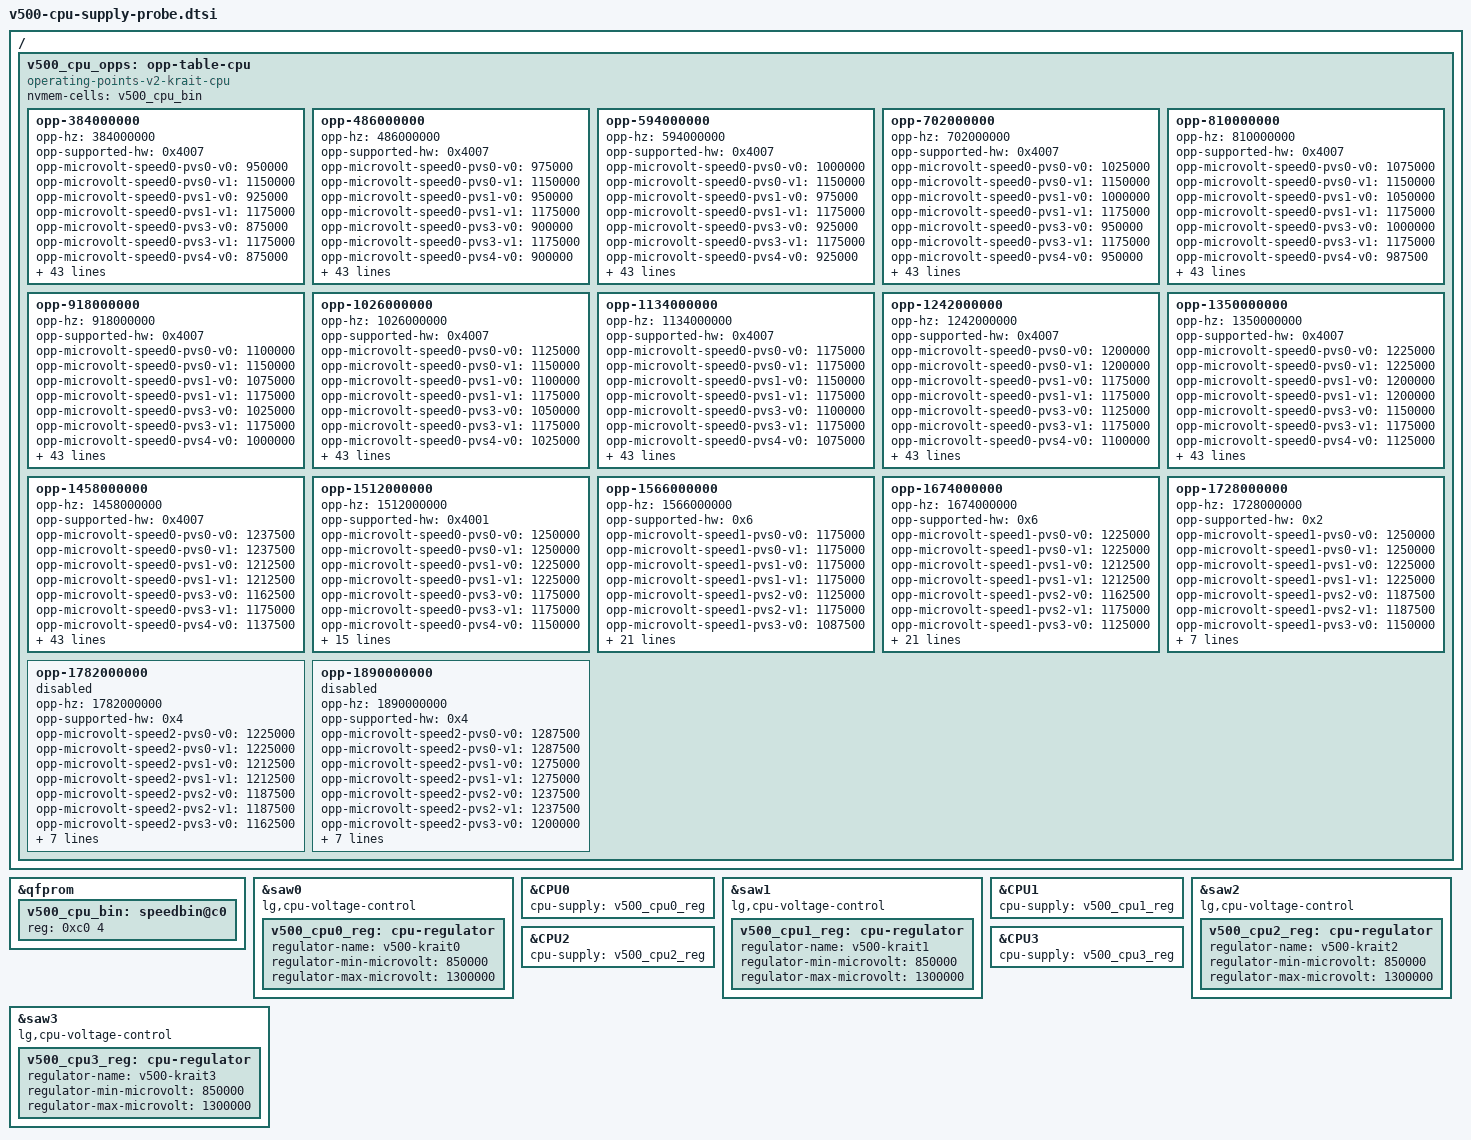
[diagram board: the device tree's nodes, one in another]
// SPDX-License-Identifier: GPL-2.0-only
/* LG acpuclock-8064.c, normal pvs_tables at 386aad263c38.
 * v0: base plus boost. v1: affected MIDRs need a 1150 mV floor before boost.
 * Only rows marked use_for_scaling by LG are CPUFreq operating points. */
&qfprom {
	v500_cpu_bin: speedbin@c0 {
		reg = <0xc0 4>;
	};
};

&saw0 {
	lg,cpu-voltage-control;
	v500_cpu0_reg: cpu-regulator {
		regulator-name = "v500-krait0";
		regulator-min-microvolt = <850000>;
		regulator-max-microvolt = <1300000>;
	};
};

&CPU0 {
	cpu-supply = <&v500_cpu0_reg>;
};

&saw1 {
	lg,cpu-voltage-control;
	v500_cpu1_reg: cpu-regulator {
		regulator-name = "v500-krait1";
		regulator-min-microvolt = <850000>;
		regulator-max-microvolt = <1300000>;
	};
};

&CPU1 {
	cpu-supply = <&v500_cpu1_reg>;
};

&saw2 {
	lg,cpu-voltage-control;
	v500_cpu2_reg: cpu-regulator {
		regulator-name = "v500-krait2";
		regulator-min-microvolt = <850000>;
		regulator-max-microvolt = <1300000>;
	};
};

&CPU2 {
	cpu-supply = <&v500_cpu2_reg>;
};

&saw3 {
	lg,cpu-voltage-control;
	v500_cpu3_reg: cpu-regulator {
		regulator-name = "v500-krait3";
		regulator-min-microvolt = <850000>;
		regulator-max-microvolt = <1300000>;
	};
};

&CPU3 {
	cpu-supply = <&v500_cpu3_reg>;
};

/ {
	/* Attach to CPUs only when L2 and shared RPM votes are implemented. */
	v500_cpu_opps: opp-table-cpu {
		compatible = "operating-points-v2-krait-cpu";
		nvmem-cells = <&v500_cpu_bin>;

		opp-384000000 {
			opp-hz = /bits/ 64 <384000000>;
			opp-supported-hw = <0x4007>;
			opp-microvolt-speed0-pvs0-v0 = <950000>;
			opp-microvolt-speed0-pvs0-v1 = <1150000>;
			opp-microvolt-speed0-pvs1-v0 = <925000>;
			opp-microvolt-speed0-pvs1-v1 = <1175000>;
			opp-microvolt-speed0-pvs3-v0 = <875000>;
			opp-microvolt-speed0-pvs3-v1 = <1175000>;
			opp-microvolt-speed0-pvs4-v0 = <875000>;
			opp-microvolt-speed0-pvs4-v1 = <1175000>;
			opp-microvolt-speed1-pvs0-v0 = <950000>;
			opp-microvolt-speed1-pvs0-v1 = <1150000>;
			opp-microvolt-speed1-pvs1-v0 = <975000>;
			opp-microvolt-speed1-pvs1-v1 = <1175000>;
			opp-microvolt-speed1-pvs2-v0 = <950000>;
			opp-microvolt-speed1-pvs2-v1 = <1175000>;
			opp-microvolt-speed1-pvs3-v0 = <925000>;
			opp-microvolt-speed1-pvs3-v1 = <1175000>;
			opp-microvolt-speed1-pvs4-v0 = <900000>;
			opp-microvolt-speed1-pvs4-v1 = <1175000>;
			opp-microvolt-speed1-pvs5-v0 = <900000>;
			opp-microvolt-speed1-pvs5-v1 = <1175000>;
			opp-microvolt-speed1-pvs6-v0 = <900000>;
			opp-microvolt-speed1-pvs6-v1 = <1175000>;
			opp-microvolt-speed2-pvs0-v0 = <950000>;
			opp-microvolt-speed2-pvs0-v1 = <1150000>;
			opp-microvolt-speed2-pvs1-v0 = <950000>;
			opp-microvolt-speed2-pvs1-v1 = <1175000>;
			opp-microvolt-speed2-pvs2-v0 = <925000>;
			opp-microvolt-speed2-pvs2-v1 = <1175000>;
			opp-microvolt-speed2-pvs3-v0 = <925000>;
			opp-microvolt-speed2-pvs3-v1 = <1175000>;
			opp-microvolt-speed2-pvs4-v0 = <900000>;
			opp-microvolt-speed2-pvs4-v1 = <1175000>;
			opp-microvolt-speed2-pvs5-v0 = <900000>;
			opp-microvolt-speed2-pvs5-v1 = <1175000>;
			opp-microvolt-speed2-pvs6-v0 = <900000>;
			opp-microvolt-speed2-pvs6-v1 = <1175000>;
			opp-microvolt-speed14-pvs0-v0 = <950000>;
			opp-microvolt-speed14-pvs0-v1 = <1150000>;
			opp-microvolt-speed14-pvs1-v0 = <975000>;
			opp-microvolt-speed14-pvs1-v1 = <1175000>;
			opp-microvolt-speed14-pvs2-v0 = <950000>;
			opp-microvolt-speed14-pvs2-v1 = <1175000>;
			opp-microvolt-speed14-pvs3-v0 = <925000>;
			opp-microvolt-speed14-pvs3-v1 = <1175000>;
			opp-microvolt-speed14-pvs4-v0 = <900000>;
			opp-microvolt-speed14-pvs4-v1 = <1175000>;
			opp-microvolt-speed14-pvs5-v0 = <900000>;
			opp-microvolt-speed14-pvs5-v1 = <1175000>;
			opp-microvolt-speed14-pvs6-v0 = <900000>;
			opp-microvolt-speed14-pvs6-v1 = <1175000>;
		};

		opp-486000000 {
			opp-hz = /bits/ 64 <486000000>;
			opp-supported-hw = <0x4007>;
			opp-microvolt-speed0-pvs0-v0 = <975000>;
			opp-microvolt-speed0-pvs0-v1 = <1150000>;
			opp-microvolt-speed0-pvs1-v0 = <950000>;
			opp-microvolt-speed0-pvs1-v1 = <1175000>;
			opp-microvolt-speed0-pvs3-v0 = <900000>;
			opp-microvolt-speed0-pvs3-v1 = <1175000>;
			opp-microvolt-speed0-pvs4-v0 = <900000>;
			opp-microvolt-speed0-pvs4-v1 = <1175000>;
			opp-microvolt-speed1-pvs0-v0 = <950000>;
			opp-microvolt-speed1-pvs0-v1 = <1150000>;
			opp-microvolt-speed1-pvs1-v0 = <975000>;
			opp-microvolt-speed1-pvs1-v1 = <1175000>;
			opp-microvolt-speed1-pvs2-v0 = <950000>;
			opp-microvolt-speed1-pvs2-v1 = <1175000>;
			opp-microvolt-speed1-pvs3-v0 = <925000>;
			opp-microvolt-speed1-pvs3-v1 = <1175000>;
			opp-microvolt-speed1-pvs4-v0 = <900000>;
			opp-microvolt-speed1-pvs4-v1 = <1175000>;
			opp-microvolt-speed1-pvs5-v0 = <900000>;
			opp-microvolt-speed1-pvs5-v1 = <1175000>;
			opp-microvolt-speed1-pvs6-v0 = <900000>;
			opp-microvolt-speed1-pvs6-v1 = <1175000>;
			opp-microvolt-speed2-pvs0-v0 = <950000>;
			opp-microvolt-speed2-pvs0-v1 = <1150000>;
			opp-microvolt-speed2-pvs1-v0 = <950000>;
			opp-microvolt-speed2-pvs1-v1 = <1175000>;
			opp-microvolt-speed2-pvs2-v0 = <925000>;
			opp-microvolt-speed2-pvs2-v1 = <1175000>;
			opp-microvolt-speed2-pvs3-v0 = <925000>;
			opp-microvolt-speed2-pvs3-v1 = <1175000>;
			opp-microvolt-speed2-pvs4-v0 = <900000>;
			opp-microvolt-speed2-pvs4-v1 = <1175000>;
			opp-microvolt-speed2-pvs5-v0 = <900000>;
			opp-microvolt-speed2-pvs5-v1 = <1175000>;
			opp-microvolt-speed2-pvs6-v0 = <900000>;
			opp-microvolt-speed2-pvs6-v1 = <1175000>;
			opp-microvolt-speed14-pvs0-v0 = <950000>;
			opp-microvolt-speed14-pvs0-v1 = <1150000>;
			opp-microvolt-speed14-pvs1-v0 = <975000>;
			opp-microvolt-speed14-pvs1-v1 = <1175000>;
			opp-microvolt-speed14-pvs2-v0 = <950000>;
			opp-microvolt-speed14-pvs2-v1 = <1175000>;
			opp-microvolt-speed14-pvs3-v0 = <925000>;
			opp-microvolt-speed14-pvs3-v1 = <1175000>;
			opp-microvolt-speed14-pvs4-v0 = <900000>;
			opp-microvolt-speed14-pvs4-v1 = <1175000>;
			opp-microvolt-speed14-pvs5-v0 = <900000>;
			opp-microvolt-speed14-pvs5-v1 = <1175000>;
			opp-microvolt-speed14-pvs6-v0 = <900000>;
			opp-microvolt-speed14-pvs6-v1 = <1175000>;
		};

		opp-594000000 {
			opp-hz = /bits/ 64 <594000000>;
			opp-supported-hw = <0x4007>;
			opp-microvolt-speed0-pvs0-v0 = <1000000>;
			opp-microvolt-speed0-pvs0-v1 = <1150000>;
			opp-microvolt-speed0-pvs1-v0 = <975000>;
			opp-microvolt-speed0-pvs1-v1 = <1175000>;
			opp-microvolt-speed0-pvs3-v0 = <925000>;
			opp-microvolt-speed0-pvs3-v1 = <1175000>;
			opp-microvolt-speed0-pvs4-v0 = <925000>;
			opp-microvolt-speed0-pvs4-v1 = <1175000>;
			opp-microvolt-speed1-pvs0-v0 = <950000>;
			opp-microvolt-speed1-pvs0-v1 = <1150000>;
			opp-microvolt-speed1-pvs1-v0 = <975000>;
			opp-microvolt-speed1-pvs1-v1 = <1175000>;
			opp-microvolt-speed1-pvs2-v0 = <950000>;
			opp-microvolt-speed1-pvs2-v1 = <1175000>;
			opp-microvolt-speed1-pvs3-v0 = <925000>;
			opp-microvolt-speed1-pvs3-v1 = <1175000>;
			opp-microvolt-speed1-pvs4-v0 = <900000>;
			opp-microvolt-speed1-pvs4-v1 = <1175000>;
			opp-microvolt-speed1-pvs5-v0 = <900000>;
			opp-microvolt-speed1-pvs5-v1 = <1175000>;
			opp-microvolt-speed1-pvs6-v0 = <900000>;
			opp-microvolt-speed1-pvs6-v1 = <1175000>;
			opp-microvolt-speed2-pvs0-v0 = <950000>;
			opp-microvolt-speed2-pvs0-v1 = <1150000>;
			opp-microvolt-speed2-pvs1-v0 = <950000>;
			opp-microvolt-speed2-pvs1-v1 = <1175000>;
			opp-microvolt-speed2-pvs2-v0 = <925000>;
			opp-microvolt-speed2-pvs2-v1 = <1175000>;
			opp-microvolt-speed2-pvs3-v0 = <925000>;
			opp-microvolt-speed2-pvs3-v1 = <1175000>;
			opp-microvolt-speed2-pvs4-v0 = <900000>;
			opp-microvolt-speed2-pvs4-v1 = <1175000>;
			opp-microvolt-speed2-pvs5-v0 = <900000>;
			opp-microvolt-speed2-pvs5-v1 = <1175000>;
			opp-microvolt-speed2-pvs6-v0 = <900000>;
			opp-microvolt-speed2-pvs6-v1 = <1175000>;
			opp-microvolt-speed14-pvs0-v0 = <950000>;
			opp-microvolt-speed14-pvs0-v1 = <1150000>;
			opp-microvolt-speed14-pvs1-v0 = <975000>;
			opp-microvolt-speed14-pvs1-v1 = <1175000>;
			opp-microvolt-speed14-pvs2-v0 = <950000>;
			opp-microvolt-speed14-pvs2-v1 = <1175000>;
			opp-microvolt-speed14-pvs3-v0 = <925000>;
			opp-microvolt-speed14-pvs3-v1 = <1175000>;
			opp-microvolt-speed14-pvs4-v0 = <900000>;
			opp-microvolt-speed14-pvs4-v1 = <1175000>;
			opp-microvolt-speed14-pvs5-v0 = <900000>;
			opp-microvolt-speed14-pvs5-v1 = <1175000>;
			opp-microvolt-speed14-pvs6-v0 = <900000>;
			opp-microvolt-speed14-pvs6-v1 = <1175000>;
		};

		opp-702000000 {
			opp-hz = /bits/ 64 <702000000>;
			opp-supported-hw = <0x4007>;
			opp-microvolt-speed0-pvs0-v0 = <1025000>;
			opp-microvolt-speed0-pvs0-v1 = <1150000>;
			opp-microvolt-speed0-pvs1-v0 = <1000000>;
			opp-microvolt-speed0-pvs1-v1 = <1175000>;
			opp-microvolt-speed0-pvs3-v0 = <950000>;
			opp-microvolt-speed0-pvs3-v1 = <1175000>;
			opp-microvolt-speed0-pvs4-v0 = <950000>;
			opp-microvolt-speed0-pvs4-v1 = <1175000>;
			opp-microvolt-speed1-pvs0-v0 = <962500>;
			opp-microvolt-speed1-pvs0-v1 = <1150000>;
			opp-microvolt-speed1-pvs1-v0 = <987500>;
			opp-microvolt-speed1-pvs1-v1 = <1175000>;
			opp-microvolt-speed1-pvs2-v0 = <950000>;
			opp-microvolt-speed1-pvs2-v1 = <1175000>;
			opp-microvolt-speed1-pvs3-v0 = <925000>;
			opp-microvolt-speed1-pvs3-v1 = <1175000>;
			opp-microvolt-speed1-pvs4-v0 = <900000>;
			opp-microvolt-speed1-pvs4-v1 = <1175000>;
			opp-microvolt-speed1-pvs5-v0 = <900000>;
			opp-microvolt-speed1-pvs5-v1 = <1175000>;
			opp-microvolt-speed1-pvs6-v0 = <900000>;
			opp-microvolt-speed1-pvs6-v1 = <1175000>;
			opp-microvolt-speed2-pvs0-v0 = <950000>;
			opp-microvolt-speed2-pvs0-v1 = <1150000>;
			opp-microvolt-speed2-pvs1-v0 = <950000>;
			opp-microvolt-speed2-pvs1-v1 = <1175000>;
			opp-microvolt-speed2-pvs2-v0 = <925000>;
			opp-microvolt-speed2-pvs2-v1 = <1175000>;
			opp-microvolt-speed2-pvs3-v0 = <925000>;
			opp-microvolt-speed2-pvs3-v1 = <1175000>;
			opp-microvolt-speed2-pvs4-v0 = <900000>;
			opp-microvolt-speed2-pvs4-v1 = <1175000>;
			opp-microvolt-speed2-pvs5-v0 = <900000>;
			opp-microvolt-speed2-pvs5-v1 = <1175000>;
			opp-microvolt-speed2-pvs6-v0 = <900000>;
			opp-microvolt-speed2-pvs6-v1 = <1175000>;
			opp-microvolt-speed14-pvs0-v0 = <962500>;
			opp-microvolt-speed14-pvs0-v1 = <1150000>;
			opp-microvolt-speed14-pvs1-v0 = <987500>;
			opp-microvolt-speed14-pvs1-v1 = <1175000>;
			opp-microvolt-speed14-pvs2-v0 = <950000>;
			opp-microvolt-speed14-pvs2-v1 = <1175000>;
			opp-microvolt-speed14-pvs3-v0 = <925000>;
			opp-microvolt-speed14-pvs3-v1 = <1175000>;
			opp-microvolt-speed14-pvs4-v0 = <900000>;
			opp-microvolt-speed14-pvs4-v1 = <1175000>;
			opp-microvolt-speed14-pvs5-v0 = <900000>;
			opp-microvolt-speed14-pvs5-v1 = <1175000>;
			opp-microvolt-speed14-pvs6-v0 = <900000>;
			opp-microvolt-speed14-pvs6-v1 = <1175000>;
		};

		opp-810000000 {
			opp-hz = /bits/ 64 <810000000>;
			opp-supported-hw = <0x4007>;
			opp-microvolt-speed0-pvs0-v0 = <1075000>;
			opp-microvolt-speed0-pvs0-v1 = <1150000>;
			opp-microvolt-speed0-pvs1-v0 = <1050000>;
			opp-microvolt-speed0-pvs1-v1 = <1175000>;
			opp-microvolt-speed0-pvs3-v0 = <1000000>;
			opp-microvolt-speed0-pvs3-v1 = <1175000>;
			opp-microvolt-speed0-pvs4-v0 = <987500>;
			opp-microvolt-speed0-pvs4-v1 = <1175000>;
			opp-microvolt-speed1-pvs0-v0 = <1000000>;
			opp-microvolt-speed1-pvs0-v1 = <1150000>;
			opp-microvolt-speed1-pvs1-v0 = <1000000>;
			opp-microvolt-speed1-pvs1-v1 = <1175000>;
			opp-microvolt-speed1-pvs2-v0 = <962500>;
			opp-microvolt-speed1-pvs2-v1 = <1175000>;
			opp-microvolt-speed1-pvs3-v0 = <925000>;
			opp-microvolt-speed1-pvs3-v1 = <1175000>;
			opp-microvolt-speed1-pvs4-v0 = <912500>;
			opp-microvolt-speed1-pvs4-v1 = <1175000>;
			opp-microvolt-speed1-pvs5-v0 = <912500>;
			opp-microvolt-speed1-pvs5-v1 = <1175000>;
			opp-microvolt-speed1-pvs6-v0 = <912500>;
			opp-microvolt-speed1-pvs6-v1 = <1175000>;
			opp-microvolt-speed2-pvs0-v0 = <962500>;
			opp-microvolt-speed2-pvs0-v1 = <1150000>;
			opp-microvolt-speed2-pvs1-v0 = <962500>;
			opp-microvolt-speed2-pvs1-v1 = <1175000>;
			opp-microvolt-speed2-pvs2-v0 = <937500>;
			opp-microvolt-speed2-pvs2-v1 = <1175000>;
			opp-microvolt-speed2-pvs3-v0 = <925000>;
			opp-microvolt-speed2-pvs3-v1 = <1175000>;
			opp-microvolt-speed2-pvs4-v0 = <912500>;
			opp-microvolt-speed2-pvs4-v1 = <1175000>;
			opp-microvolt-speed2-pvs5-v0 = <912500>;
			opp-microvolt-speed2-pvs5-v1 = <1175000>;
			opp-microvolt-speed2-pvs6-v0 = <912500>;
			opp-microvolt-speed2-pvs6-v1 = <1175000>;
			opp-microvolt-speed14-pvs0-v0 = <1000000>;
			opp-microvolt-speed14-pvs0-v1 = <1150000>;
			opp-microvolt-speed14-pvs1-v0 = <1000000>;
			opp-microvolt-speed14-pvs1-v1 = <1175000>;
			opp-microvolt-speed14-pvs2-v0 = <962500>;
			opp-microvolt-speed14-pvs2-v1 = <1175000>;
			opp-microvolt-speed14-pvs3-v0 = <925000>;
			opp-microvolt-speed14-pvs3-v1 = <1175000>;
			opp-microvolt-speed14-pvs4-v0 = <912500>;
			opp-microvolt-speed14-pvs4-v1 = <1175000>;
			opp-microvolt-speed14-pvs5-v0 = <912500>;
			opp-microvolt-speed14-pvs5-v1 = <1175000>;
			opp-microvolt-speed14-pvs6-v0 = <912500>;
			opp-microvolt-speed14-pvs6-v1 = <1175000>;
		};

		opp-918000000 {
			opp-hz = /bits/ 64 <918000000>;
			opp-supported-hw = <0x4007>;
			opp-microvolt-speed0-pvs0-v0 = <1100000>;
			opp-microvolt-speed0-pvs0-v1 = <1150000>;
			opp-microvolt-speed0-pvs1-v0 = <1075000>;
			opp-microvolt-speed0-pvs1-v1 = <1175000>;
			opp-microvolt-speed0-pvs3-v0 = <1025000>;
			opp-microvolt-speed0-pvs3-v1 = <1175000>;
			opp-microvolt-speed0-pvs4-v0 = <1000000>;
			opp-microvolt-speed0-pvs4-v1 = <1175000>;
			opp-microvolt-speed1-pvs0-v0 = <1025000>;
			opp-microvolt-speed1-pvs0-v1 = <1150000>;
			opp-microvolt-speed1-pvs1-v0 = <1025000>;
			opp-microvolt-speed1-pvs1-v1 = <1175000>;
			opp-microvolt-speed1-pvs2-v0 = <975000>;
			opp-microvolt-speed1-pvs2-v1 = <1175000>;
			opp-microvolt-speed1-pvs3-v0 = <950000>;
			opp-microvolt-speed1-pvs3-v1 = <1175000>;
			opp-microvolt-speed1-pvs4-v0 = <925000>;
			opp-microvolt-speed1-pvs4-v1 = <1175000>;
			opp-microvolt-speed1-pvs5-v0 = <925000>;
			opp-microvolt-speed1-pvs5-v1 = <1175000>;
			opp-microvolt-speed1-pvs6-v0 = <925000>;
			opp-microvolt-speed1-pvs6-v1 = <1175000>;
			opp-microvolt-speed2-pvs0-v0 = <975000>;
			opp-microvolt-speed2-pvs0-v1 = <1150000>;
			opp-microvolt-speed2-pvs1-v0 = <975000>;
			opp-microvolt-speed2-pvs1-v1 = <1175000>;
			opp-microvolt-speed2-pvs2-v0 = <950000>;
			opp-microvolt-speed2-pvs2-v1 = <1175000>;
			opp-microvolt-speed2-pvs3-v0 = <937500>;
			opp-microvolt-speed2-pvs3-v1 = <1175000>;
			opp-microvolt-speed2-pvs4-v0 = <925000>;
			opp-microvolt-speed2-pvs4-v1 = <1175000>;
			opp-microvolt-speed2-pvs5-v0 = <925000>;
			opp-microvolt-speed2-pvs5-v1 = <1175000>;
			opp-microvolt-speed2-pvs6-v0 = <925000>;
			opp-microvolt-speed2-pvs6-v1 = <1175000>;
			opp-microvolt-speed14-pvs0-v0 = <1025000>;
			opp-microvolt-speed14-pvs0-v1 = <1150000>;
			opp-microvolt-speed14-pvs1-v0 = <1025000>;
			opp-microvolt-speed14-pvs1-v1 = <1175000>;
			opp-microvolt-speed14-pvs2-v0 = <975000>;
			opp-microvolt-speed14-pvs2-v1 = <1175000>;
			opp-microvolt-speed14-pvs3-v0 = <950000>;
			opp-microvolt-speed14-pvs3-v1 = <1175000>;
			opp-microvolt-speed14-pvs4-v0 = <925000>;
			opp-microvolt-speed14-pvs4-v1 = <1175000>;
			opp-microvolt-speed14-pvs5-v0 = <925000>;
			opp-microvolt-speed14-pvs5-v1 = <1175000>;
			opp-microvolt-speed14-pvs6-v0 = <925000>;
			opp-microvolt-speed14-pvs6-v1 = <1175000>;
		};

		opp-1026000000 {
			opp-hz = /bits/ 64 <1026000000>;
			opp-supported-hw = <0x4007>;
			opp-microvolt-speed0-pvs0-v0 = <1125000>;
			opp-microvolt-speed0-pvs0-v1 = <1150000>;
			opp-microvolt-speed0-pvs1-v0 = <1100000>;
			opp-microvolt-speed0-pvs1-v1 = <1175000>;
			opp-microvolt-speed0-pvs3-v0 = <1050000>;
			opp-microvolt-speed0-pvs3-v1 = <1175000>;
			opp-microvolt-speed0-pvs4-v0 = <1025000>;
			opp-microvolt-speed0-pvs4-v1 = <1175000>;
			opp-microvolt-speed1-pvs0-v0 = <1037500>;
			opp-microvolt-speed1-pvs0-v1 = <1150000>;
			opp-microvolt-speed1-pvs1-v0 = <1037500>;
			opp-microvolt-speed1-pvs1-v1 = <1175000>;
			opp-microvolt-speed1-pvs2-v0 = <1000000>;
			opp-microvolt-speed1-pvs2-v1 = <1175000>;
			opp-microvolt-speed1-pvs3-v0 = <975000>;
			opp-microvolt-speed1-pvs3-v1 = <1175000>;
			opp-microvolt-speed1-pvs4-v0 = <950000>;
			opp-microvolt-speed1-pvs4-v1 = <1175000>;
			opp-microvolt-speed1-pvs5-v0 = <950000>;
			opp-microvolt-speed1-pvs5-v1 = <1175000>;
			opp-microvolt-speed1-pvs6-v0 = <950000>;
			opp-microvolt-speed1-pvs6-v1 = <1175000>;
			opp-microvolt-speed2-pvs0-v0 = <1000000>;
			opp-microvolt-speed2-pvs0-v1 = <1150000>;
			opp-microvolt-speed2-pvs1-v0 = <1000000>;
			opp-microvolt-speed2-pvs1-v1 = <1175000>;
			opp-microvolt-speed2-pvs2-v0 = <975000>;
			opp-microvolt-speed2-pvs2-v1 = <1175000>;
			opp-microvolt-speed2-pvs3-v0 = <962500>;
			opp-microvolt-speed2-pvs3-v1 = <1175000>;
			opp-microvolt-speed2-pvs4-v0 = <950000>;
			opp-microvolt-speed2-pvs4-v1 = <1175000>;
			opp-microvolt-speed2-pvs5-v0 = <950000>;
			opp-microvolt-speed2-pvs5-v1 = <1175000>;
			opp-microvolt-speed2-pvs6-v0 = <950000>;
			opp-microvolt-speed2-pvs6-v1 = <1175000>;
			opp-microvolt-speed14-pvs0-v0 = <1037500>;
			opp-microvolt-speed14-pvs0-v1 = <1150000>;
			opp-microvolt-speed14-pvs1-v0 = <1037500>;
			opp-microvolt-speed14-pvs1-v1 = <1175000>;
			opp-microvolt-speed14-pvs2-v0 = <1000000>;
			opp-microvolt-speed14-pvs2-v1 = <1175000>;
			opp-microvolt-speed14-pvs3-v0 = <975000>;
			opp-microvolt-speed14-pvs3-v1 = <1175000>;
			opp-microvolt-speed14-pvs4-v0 = <950000>;
			opp-microvolt-speed14-pvs4-v1 = <1175000>;
			opp-microvolt-speed14-pvs5-v0 = <950000>;
			opp-microvolt-speed14-pvs5-v1 = <1175000>;
			opp-microvolt-speed14-pvs6-v0 = <950000>;
			opp-microvolt-speed14-pvs6-v1 = <1175000>;
		};

		opp-1134000000 {
			opp-hz = /bits/ 64 <1134000000>;
			opp-supported-hw = <0x4007>;
			opp-microvolt-speed0-pvs0-v0 = <1175000>;
			opp-microvolt-speed0-pvs0-v1 = <1175000>;
			opp-microvolt-speed0-pvs1-v0 = <1150000>;
			opp-microvolt-speed0-pvs1-v1 = <1175000>;
			opp-microvolt-speed0-pvs3-v0 = <1100000>;
			opp-microvolt-speed0-pvs3-v1 = <1175000>;
			opp-microvolt-speed0-pvs4-v0 = <1075000>;
			opp-microvolt-speed0-pvs4-v1 = <1175000>;
			opp-microvolt-speed1-pvs0-v0 = <1075000>;
			opp-microvolt-speed1-pvs0-v1 = <1150000>;
			opp-microvolt-speed1-pvs1-v0 = <1062500>;
			opp-microvolt-speed1-pvs1-v1 = <1175000>;
			opp-microvolt-speed1-pvs2-v0 = <1025000>;
			opp-microvolt-speed1-pvs2-v1 = <1175000>;
			opp-microvolt-speed1-pvs3-v0 = <1000000>;
			opp-microvolt-speed1-pvs3-v1 = <1175000>;
			opp-microvolt-speed1-pvs4-v0 = <975000>;
			opp-microvolt-speed1-pvs4-v1 = <1175000>;
			opp-microvolt-speed1-pvs5-v0 = <962500>;
			opp-microvolt-speed1-pvs5-v1 = <1175000>;
			opp-microvolt-speed1-pvs6-v0 = <962500>;
			opp-microvolt-speed1-pvs6-v1 = <1175000>;
			opp-microvolt-speed2-pvs0-v0 = <1025000>;
			opp-microvolt-speed2-pvs0-v1 = <1150000>;
			opp-microvolt-speed2-pvs1-v0 = <1025000>;
			opp-microvolt-speed2-pvs1-v1 = <1175000>;
			opp-microvolt-speed2-pvs2-v0 = <1000000>;
			opp-microvolt-speed2-pvs2-v1 = <1175000>;
			opp-microvolt-speed2-pvs3-v0 = <987500>;
			opp-microvolt-speed2-pvs3-v1 = <1175000>;
			opp-microvolt-speed2-pvs4-v0 = <975000>;
			opp-microvolt-speed2-pvs4-v1 = <1175000>;
			opp-microvolt-speed2-pvs5-v0 = <962500>;
			opp-microvolt-speed2-pvs5-v1 = <1175000>;
			opp-microvolt-speed2-pvs6-v0 = <962500>;
			opp-microvolt-speed2-pvs6-v1 = <1175000>;
			opp-microvolt-speed14-pvs0-v0 = <1075000>;
			opp-microvolt-speed14-pvs0-v1 = <1150000>;
			opp-microvolt-speed14-pvs1-v0 = <1062500>;
			opp-microvolt-speed14-pvs1-v1 = <1175000>;
			opp-microvolt-speed14-pvs2-v0 = <1025000>;
			opp-microvolt-speed14-pvs2-v1 = <1175000>;
			opp-microvolt-speed14-pvs3-v0 = <1000000>;
			opp-microvolt-speed14-pvs3-v1 = <1175000>;
			opp-microvolt-speed14-pvs4-v0 = <975000>;
			opp-microvolt-speed14-pvs4-v1 = <1175000>;
			opp-microvolt-speed14-pvs5-v0 = <962500>;
			opp-microvolt-speed14-pvs5-v1 = <1175000>;
			opp-microvolt-speed14-pvs6-v0 = <962500>;
			opp-microvolt-speed14-pvs6-v1 = <1175000>;
		};

		opp-1242000000 {
			opp-hz = /bits/ 64 <1242000000>;
			opp-supported-hw = <0x4007>;
			opp-microvolt-speed0-pvs0-v0 = <1200000>;
			opp-microvolt-speed0-pvs0-v1 = <1200000>;
			opp-microvolt-speed0-pvs1-v0 = <1175000>;
			opp-microvolt-speed0-pvs1-v1 = <1175000>;
			opp-microvolt-speed0-pvs3-v0 = <1125000>;
			opp-microvolt-speed0-pvs3-v1 = <1175000>;
			opp-microvolt-speed0-pvs4-v0 = <1100000>;
			opp-microvolt-speed0-pvs4-v1 = <1175000>;
			opp-microvolt-speed1-pvs0-v0 = <1087500>;
			opp-microvolt-speed1-pvs0-v1 = <1150000>;
			opp-microvolt-speed1-pvs1-v0 = <1075000>;
			opp-microvolt-speed1-pvs1-v1 = <1175000>;
			opp-microvolt-speed1-pvs2-v0 = <1037500>;
			opp-microvolt-speed1-pvs2-v1 = <1175000>;
			opp-microvolt-speed1-pvs3-v0 = <1012500>;
			opp-microvolt-speed1-pvs3-v1 = <1175000>;
			opp-microvolt-speed1-pvs4-v0 = <987500>;
			opp-microvolt-speed1-pvs4-v1 = <1175000>;
			opp-microvolt-speed1-pvs5-v0 = <975000>;
			opp-microvolt-speed1-pvs5-v1 = <1175000>;
			opp-microvolt-speed1-pvs6-v0 = <975000>;
			opp-microvolt-speed1-pvs6-v1 = <1175000>;
			opp-microvolt-speed2-pvs0-v0 = <1037500>;
			opp-microvolt-speed2-pvs0-v1 = <1150000>;
			opp-microvolt-speed2-pvs1-v0 = <1037500>;
			opp-microvolt-speed2-pvs1-v1 = <1175000>;
			opp-microvolt-speed2-pvs2-v0 = <1012500>;
			opp-microvolt-speed2-pvs2-v1 = <1175000>;
			opp-microvolt-speed2-pvs3-v0 = <1000000>;
			opp-microvolt-speed2-pvs3-v1 = <1175000>;
			opp-microvolt-speed2-pvs4-v0 = <987500>;
			opp-microvolt-speed2-pvs4-v1 = <1175000>;
			opp-microvolt-speed2-pvs5-v0 = <975000>;
			opp-microvolt-speed2-pvs5-v1 = <1175000>;
			opp-microvolt-speed2-pvs6-v0 = <975000>;
			opp-microvolt-speed2-pvs6-v1 = <1175000>;
			opp-microvolt-speed14-pvs0-v0 = <1087500>;
			opp-microvolt-speed14-pvs0-v1 = <1150000>;
			opp-microvolt-speed14-pvs1-v0 = <1075000>;
			opp-microvolt-speed14-pvs1-v1 = <1175000>;
			opp-microvolt-speed14-pvs2-v0 = <1037500>;
			opp-microvolt-speed14-pvs2-v1 = <1175000>;
			opp-microvolt-speed14-pvs3-v0 = <1012500>;
			opp-microvolt-speed14-pvs3-v1 = <1175000>;
			opp-microvolt-speed14-pvs4-v0 = <987500>;
			opp-microvolt-speed14-pvs4-v1 = <1175000>;
			opp-microvolt-speed14-pvs5-v0 = <975000>;
			opp-microvolt-speed14-pvs5-v1 = <1175000>;
			opp-microvolt-speed14-pvs6-v0 = <975000>;
			opp-microvolt-speed14-pvs6-v1 = <1175000>;
		};

		opp-1350000000 {
			opp-hz = /bits/ 64 <1350000000>;
			opp-supported-hw = <0x4007>;
			opp-microvolt-speed0-pvs0-v0 = <1225000>;
			opp-microvolt-speed0-pvs0-v1 = <1225000>;
			opp-microvolt-speed0-pvs1-v0 = <1200000>;
			opp-microvolt-speed0-pvs1-v1 = <1200000>;
			opp-microvolt-speed0-pvs3-v0 = <1150000>;
			opp-microvolt-speed0-pvs3-v1 = <1175000>;
			opp-microvolt-speed0-pvs4-v0 = <1125000>;
			opp-microvolt-speed0-pvs4-v1 = <1175000>;
			opp-microvolt-speed1-pvs0-v0 = <1125000>;
			opp-microvolt-speed1-pvs0-v1 = <1150000>;
			opp-microvolt-speed1-pvs1-v0 = <1112500>;
			opp-microvolt-speed1-pvs1-v1 = <1175000>;
			opp-microvolt-speed1-pvs2-v0 = <1062500>;
			opp-microvolt-speed1-pvs2-v1 = <1175000>;
			opp-microvolt-speed1-pvs3-v0 = <1025000>;
			opp-microvolt-speed1-pvs3-v1 = <1175000>;
			opp-microvolt-speed1-pvs4-v0 = <1000000>;
			opp-microvolt-speed1-pvs4-v1 = <1175000>;
			opp-microvolt-speed1-pvs5-v0 = <987500>;
			opp-microvolt-speed1-pvs5-v1 = <1175000>;
			opp-microvolt-speed1-pvs6-v0 = <987500>;
			opp-microvolt-speed1-pvs6-v1 = <1175000>;
			opp-microvolt-speed2-pvs0-v0 = <1062500>;
			opp-microvolt-speed2-pvs0-v1 = <1150000>;
			opp-microvolt-speed2-pvs1-v0 = <1062500>;
			opp-microvolt-speed2-pvs1-v1 = <1175000>;
			opp-microvolt-speed2-pvs2-v0 = <1037500>;
			opp-microvolt-speed2-pvs2-v1 = <1175000>;
			opp-microvolt-speed2-pvs3-v0 = <1025000>;
			opp-microvolt-speed2-pvs3-v1 = <1175000>;
			opp-microvolt-speed2-pvs4-v0 = <1000000>;
			opp-microvolt-speed2-pvs4-v1 = <1175000>;
			opp-microvolt-speed2-pvs5-v0 = <987500>;
			opp-microvolt-speed2-pvs5-v1 = <1175000>;
			opp-microvolt-speed2-pvs6-v0 = <987500>;
			opp-microvolt-speed2-pvs6-v1 = <1175000>;
			opp-microvolt-speed14-pvs0-v0 = <1125000>;
			opp-microvolt-speed14-pvs0-v1 = <1150000>;
			opp-microvolt-speed14-pvs1-v0 = <1112500>;
			opp-microvolt-speed14-pvs1-v1 = <1175000>;
			opp-microvolt-speed14-pvs2-v0 = <1062500>;
			opp-microvolt-speed14-pvs2-v1 = <1175000>;
			opp-microvolt-speed14-pvs3-v0 = <1025000>;
			opp-microvolt-speed14-pvs3-v1 = <1175000>;
			opp-microvolt-speed14-pvs4-v0 = <1000000>;
			opp-microvolt-speed14-pvs4-v1 = <1175000>;
			opp-microvolt-speed14-pvs5-v0 = <987500>;
			opp-microvolt-speed14-pvs5-v1 = <1175000>;
			opp-microvolt-speed14-pvs6-v0 = <987500>;
			opp-microvolt-speed14-pvs6-v1 = <1175000>;
		};

		opp-1458000000 {
			opp-hz = /bits/ 64 <1458000000>;
			opp-supported-hw = <0x4007>;
			opp-microvolt-speed0-pvs0-v0 = <1237500>;
			opp-microvolt-speed0-pvs0-v1 = <1237500>;
			opp-microvolt-speed0-pvs1-v0 = <1212500>;
			opp-microvolt-speed0-pvs1-v1 = <1212500>;
			opp-microvolt-speed0-pvs3-v0 = <1162500>;
			opp-microvolt-speed0-pvs3-v1 = <1175000>;
			opp-microvolt-speed0-pvs4-v0 = <1137500>;
			opp-microvolt-speed0-pvs4-v1 = <1175000>;
			opp-microvolt-speed1-pvs0-v0 = <1150000>;
			opp-microvolt-speed1-pvs0-v1 = <1150000>;
			opp-microvolt-speed1-pvs1-v0 = <1137500>;
			opp-microvolt-speed1-pvs1-v1 = <1175000>;
			opp-microvolt-speed1-pvs2-v0 = <1100000>;
			opp-microvolt-speed1-pvs2-v1 = <1175000>;
			opp-microvolt-speed1-pvs3-v0 = <1062500>;
			opp-microvolt-speed1-pvs3-v1 = <1175000>;
			opp-microvolt-speed1-pvs4-v0 = <1025000>;
			opp-microvolt-speed1-pvs4-v1 = <1175000>;
			opp-microvolt-speed1-pvs5-v0 = <1012500>;
			opp-microvolt-speed1-pvs5-v1 = <1175000>;
			opp-microvolt-speed1-pvs6-v0 = <1000000>;
			opp-microvolt-speed1-pvs6-v1 = <1175000>;
			opp-microvolt-speed2-pvs0-v0 = <1100000>;
			opp-microvolt-speed2-pvs0-v1 = <1150000>;
			opp-microvolt-speed2-pvs1-v0 = <1100000>;
			opp-microvolt-speed2-pvs1-v1 = <1175000>;
			opp-microvolt-speed2-pvs2-v0 = <1075000>;
			opp-microvolt-speed2-pvs2-v1 = <1175000>;
			opp-microvolt-speed2-pvs3-v0 = <1050000>;
			opp-microvolt-speed2-pvs3-v1 = <1175000>;
			opp-microvolt-speed2-pvs4-v0 = <1025000>;
			opp-microvolt-speed2-pvs4-v1 = <1175000>;
			opp-microvolt-speed2-pvs5-v0 = <1012500>;
			opp-microvolt-speed2-pvs5-v1 = <1175000>;
			opp-microvolt-speed2-pvs6-v0 = <1000000>;
			opp-microvolt-speed2-pvs6-v1 = <1175000>;
			opp-microvolt-speed14-pvs0-v0 = <1150000>;
			opp-microvolt-speed14-pvs0-v1 = <1150000>;
			opp-microvolt-speed14-pvs1-v0 = <1137500>;
			opp-microvolt-speed14-pvs1-v1 = <1175000>;
			opp-microvolt-speed14-pvs2-v0 = <1100000>;
			opp-microvolt-speed14-pvs2-v1 = <1175000>;
			opp-microvolt-speed14-pvs3-v0 = <1062500>;
			opp-microvolt-speed14-pvs3-v1 = <1175000>;
			opp-microvolt-speed14-pvs4-v0 = <1025000>;
			opp-microvolt-speed14-pvs4-v1 = <1175000>;
			opp-microvolt-speed14-pvs5-v0 = <1012500>;
			opp-microvolt-speed14-pvs5-v1 = <1175000>;
			opp-microvolt-speed14-pvs6-v0 = <1000000>;
			opp-microvolt-speed14-pvs6-v1 = <1175000>;
		};

		opp-1512000000 {
			opp-hz = /bits/ 64 <1512000000>;
			opp-supported-hw = <0x4001>;
			opp-microvolt-speed0-pvs0-v0 = <1250000>;
			opp-microvolt-speed0-pvs0-v1 = <1250000>;
			opp-microvolt-speed0-pvs1-v0 = <1225000>;
			opp-microvolt-speed0-pvs1-v1 = <1225000>;
			opp-microvolt-speed0-pvs3-v0 = <1175000>;
			opp-microvolt-speed0-pvs3-v1 = <1175000>;
			opp-microvolt-speed0-pvs4-v0 = <1150000>;
			opp-microvolt-speed0-pvs4-v1 = <1175000>;
			opp-microvolt-speed14-pvs0-v0 = <1162500>;
			opp-microvolt-speed14-pvs0-v1 = <1162500>;
			opp-microvolt-speed14-pvs1-v0 = <1150000>;
			opp-microvolt-speed14-pvs1-v1 = <1175000>;
			opp-microvolt-speed14-pvs2-v0 = <1112500>;
			opp-microvolt-speed14-pvs2-v1 = <1175000>;
			opp-microvolt-speed14-pvs3-v0 = <1075000>;
			opp-microvolt-speed14-pvs3-v1 = <1175000>;
			opp-microvolt-speed14-pvs4-v0 = <1037500>;
			opp-microvolt-speed14-pvs4-v1 = <1175000>;
			opp-microvolt-speed14-pvs5-v0 = <1025000>;
			opp-microvolt-speed14-pvs5-v1 = <1175000>;
			opp-microvolt-speed14-pvs6-v0 = <1012500>;
			opp-microvolt-speed14-pvs6-v1 = <1175000>;
		};

		opp-1566000000 {
			opp-hz = /bits/ 64 <1566000000>;
			opp-supported-hw = <0x6>;
			opp-microvolt-speed1-pvs0-v0 = <1175000>;
			opp-microvolt-speed1-pvs0-v1 = <1175000>;
			opp-microvolt-speed1-pvs1-v0 = <1175000>;
			opp-microvolt-speed1-pvs1-v1 = <1175000>;
			opp-microvolt-speed1-pvs2-v0 = <1125000>;
			opp-microvolt-speed1-pvs2-v1 = <1175000>;
			opp-microvolt-speed1-pvs3-v0 = <1087500>;
			opp-microvolt-speed1-pvs3-v1 = <1175000>;
			opp-microvolt-speed1-pvs4-v0 = <1062500>;
			opp-microvolt-speed1-pvs4-v1 = <1175000>;
			opp-microvolt-speed1-pvs5-v0 = <1037500>;
			opp-microvolt-speed1-pvs5-v1 = <1175000>;
			opp-microvolt-speed1-pvs6-v0 = <1025000>;
			opp-microvolt-speed1-pvs6-v1 = <1175000>;
			opp-microvolt-speed2-pvs0-v0 = <1125000>;
			opp-microvolt-speed2-pvs0-v1 = <1150000>;
			opp-microvolt-speed2-pvs1-v0 = <1125000>;
			opp-microvolt-speed2-pvs1-v1 = <1175000>;
			opp-microvolt-speed2-pvs2-v0 = <1100000>;
			opp-microvolt-speed2-pvs2-v1 = <1175000>;
			opp-microvolt-speed2-pvs3-v0 = <1075000>;
			opp-microvolt-speed2-pvs3-v1 = <1175000>;
			opp-microvolt-speed2-pvs4-v0 = <1062500>;
			opp-microvolt-speed2-pvs4-v1 = <1175000>;
			opp-microvolt-speed2-pvs5-v0 = <1037500>;
			opp-microvolt-speed2-pvs5-v1 = <1175000>;
			opp-microvolt-speed2-pvs6-v0 = <1025000>;
			opp-microvolt-speed2-pvs6-v1 = <1175000>;
		};

		opp-1674000000 {
			opp-hz = /bits/ 64 <1674000000>;
			opp-supported-hw = <0x6>;
			opp-microvolt-speed1-pvs0-v0 = <1225000>;
			opp-microvolt-speed1-pvs0-v1 = <1225000>;
			opp-microvolt-speed1-pvs1-v0 = <1212500>;
			opp-microvolt-speed1-pvs1-v1 = <1212500>;
			opp-microvolt-speed1-pvs2-v0 = <1162500>;
			opp-microvolt-speed1-pvs2-v1 = <1175000>;
			opp-microvolt-speed1-pvs3-v0 = <1125000>;
			opp-microvolt-speed1-pvs3-v1 = <1175000>;
			opp-microvolt-speed1-pvs4-v0 = <1100000>;
			opp-microvolt-speed1-pvs4-v1 = <1175000>;
			opp-microvolt-speed1-pvs5-v0 = <1075000>;
			opp-microvolt-speed1-pvs5-v1 = <1175000>;
			opp-microvolt-speed1-pvs6-v0 = <1050000>;
			opp-microvolt-speed1-pvs6-v1 = <1175000>;
			opp-microvolt-speed2-pvs0-v0 = <1175000>;
			opp-microvolt-speed2-pvs0-v1 = <1175000>;
			opp-microvolt-speed2-pvs1-v0 = <1162500>;
			opp-microvolt-speed2-pvs1-v1 = <1175000>;
			opp-microvolt-speed2-pvs2-v0 = <1137500>;
			opp-microvolt-speed2-pvs2-v1 = <1175000>;
			opp-microvolt-speed2-pvs3-v0 = <1112500>;
			opp-microvolt-speed2-pvs3-v1 = <1175000>;
			opp-microvolt-speed2-pvs4-v0 = <1100000>;
			opp-microvolt-speed2-pvs4-v1 = <1175000>;
			opp-microvolt-speed2-pvs5-v0 = <1075000>;
			opp-microvolt-speed2-pvs5-v1 = <1175000>;
			opp-microvolt-speed2-pvs6-v0 = <1050000>;
			opp-microvolt-speed2-pvs6-v1 = <1175000>;
		};

		opp-1728000000 {
			opp-hz = /bits/ 64 <1728000000>;
			opp-supported-hw = <0x2>;
			opp-microvolt-speed1-pvs0-v0 = <1250000>;
			opp-microvolt-speed1-pvs0-v1 = <1250000>;
			opp-microvolt-speed1-pvs1-v0 = <1225000>;
			opp-microvolt-speed1-pvs1-v1 = <1225000>;
			opp-microvolt-speed1-pvs2-v0 = <1187500>;
			opp-microvolt-speed1-pvs2-v1 = <1187500>;
			opp-microvolt-speed1-pvs3-v0 = <1150000>;
			opp-microvolt-speed1-pvs3-v1 = <1175000>;
			opp-microvolt-speed1-pvs4-v0 = <1125000>;
			opp-microvolt-speed1-pvs4-v1 = <1175000>;
			opp-microvolt-speed1-pvs5-v0 = <1100000>;
			opp-microvolt-speed1-pvs5-v1 = <1175000>;
			opp-microvolt-speed1-pvs6-v0 = <1075000>;
			opp-microvolt-speed1-pvs6-v1 = <1175000>;
		};

		opp-1782000000 {
			opp-hz = /bits/ 64 <1782000000>;
			opp-supported-hw = <0x4>;
			status = "disabled"; /* V500 project frequency ceiling */
			opp-microvolt-speed2-pvs0-v0 = <1225000>;
			opp-microvolt-speed2-pvs0-v1 = <1225000>;
			opp-microvolt-speed2-pvs1-v0 = <1212500>;
			opp-microvolt-speed2-pvs1-v1 = <1212500>;
			opp-microvolt-speed2-pvs2-v0 = <1187500>;
			opp-microvolt-speed2-pvs2-v1 = <1187500>;
			opp-microvolt-speed2-pvs3-v0 = <1162500>;
			opp-microvolt-speed2-pvs3-v1 = <1175000>;
			opp-microvolt-speed2-pvs4-v0 = <1137500>;
			opp-microvolt-speed2-pvs4-v1 = <1175000>;
			opp-microvolt-speed2-pvs5-v0 = <1112500>;
			opp-microvolt-speed2-pvs5-v1 = <1175000>;
			opp-microvolt-speed2-pvs6-v0 = <1087500>;
			opp-microvolt-speed2-pvs6-v1 = <1175000>;
		};

		opp-1890000000 {
			opp-hz = /bits/ 64 <1890000000>;
			opp-supported-hw = <0x4>;
			status = "disabled"; /* V500 project frequency ceiling */
			opp-microvolt-speed2-pvs0-v0 = <1287500>;
			opp-microvolt-speed2-pvs0-v1 = <1287500>;
			opp-microvolt-speed2-pvs1-v0 = <1275000>;
			opp-microvolt-speed2-pvs1-v1 = <1275000>;
			opp-microvolt-speed2-pvs2-v0 = <1237500>;
			opp-microvolt-speed2-pvs2-v1 = <1237500>;
			opp-microvolt-speed2-pvs3-v0 = <1200000>;
			opp-microvolt-speed2-pvs3-v1 = <1200000>;
			opp-microvolt-speed2-pvs4-v0 = <1175000>;
			opp-microvolt-speed2-pvs4-v1 = <1175000>;
			opp-microvolt-speed2-pvs5-v0 = <1150000>;
			opp-microvolt-speed2-pvs5-v1 = <1175000>;
			opp-microvolt-speed2-pvs6-v0 = <1125000>;
			opp-microvolt-speed2-pvs6-v1 = <1175000>;
		};
	};
};
